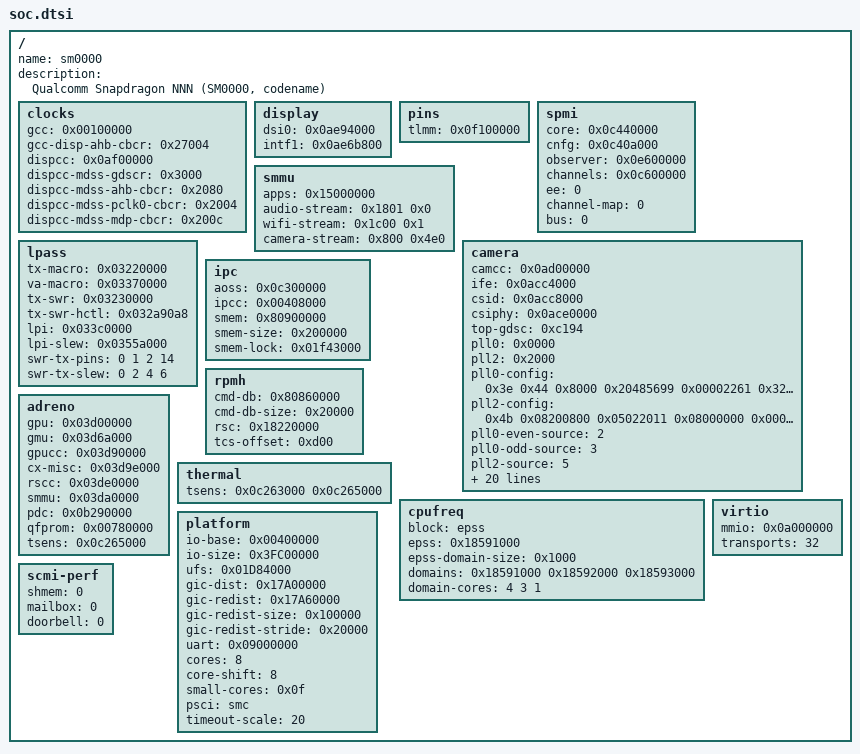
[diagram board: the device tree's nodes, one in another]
/dts-v1/;

// A SoC file with every key, explained: what goes in a package's soc.dtsi, beside its board.dts.
// `tools/boards.py new NAME --soc SOC --dts FILE` writes one with what your device tree says; this is the
// reference. A section is needed only by what uses it: a board with `features = <>;` and a "soft"
// backlight needs none of them. Addresses are the SoC's physical ones, as the Android device tree has
// them (the SoC's .dtsi).

/ {
	name = "sm0000";                        // what the board file gives as `soc`
	description = "Qualcomm Snapdragon NNN (SM0000, codename)";

	// The clocks the display block's registers need before they can be read: for a "dcs" backlight and
	// the feature "display-scan". The addresses are in the tree; the offsets are not -- they are in Linux's
	// clock drivers for the SoC (gcc-CODENAME.c, dispcc-CODENAME.c).
	clocks {
		gcc = <0x00100000>;             // clock-controller@100000 (qcom,CODENAME-gcc); the only key of this section
		                                // that the part drivers need
		gcc-disp-ahb-cbcr = <0x27004>;  // gcc_disp_ahb_clk: its .halt_reg
		dispcc = <0x0af00000>;          // clock-controller@af00000 (qcom,CODENAME-dispcc)
		dispcc-mdss-gdscr = <0x3000>;   // the display block's power switch (mdss_core_gdsc): its .gdscr
		dispcc-mdss-ahb-cbcr = <0x2080>; // disp_cc_mdss_ahb_clk
		dispcc-mdss-pclk0-cbcr = <0x2004>; // disp_cc_mdss_pclk0_clk  } optional: only looked at, by display_probe=1
		dispcc-mdss-mdp-cbcr = <0x200c>; // disp_cc_mdss_mdp_clk    }
	};

	display {
		dsi0 = <0x0ae94000>;            // the first DSI controller (cell-index 0), reg "dsi_ctrl"
		intf1 = <0x0ae6b800>;           // optional, for "display-scan": the same node's reg "mdp_intf_base"
	};

	// The SoC's own pins (TLMM), for the part drivers that drive them: the touch controllers', the speaker
	// amplifier's, the haptic motor's, the cameras'.
	pins {
		tlmm = <0x0f100000>;            // where GPIO 0's registers are; GPIO n's are 0x1000 n further. The pin
		                                // controller's node (qcom,CODENAME-pinctrl): in Linux's trees its reg; in
		                                // the vendor's, whose reg is the whole 16 MiB block, 0x100000 above it
	};

	// The PMIC arbiter (qcom,spmi-pmic-arb), by its reg-names: for the features "buttons-pmic",
	// "torch-pm8350c" and "camera-sm7325".
	spmi {
		core = <0x0c440000>;            // "core"
		cnfg = <0x0c40a000>;            // "cnfg"
		observer = <0x0e600000>;        // "obsrvr": reads
		channels = <0x0c600000>;        // "chnls": writes; optional, needed only by the drivers that write to a PMIC
		ee = <0>;                       // qcom,ee; optional, 0 if left out
		channel-map = <0>;              // arbiter version 8 only: its table of channels (the "core" node's
		//                              // second block); cnfg is then the table of owners, observer and
		//                              // channels 0x20 and 0x200 a channel (Linux spmi-pmic-arb.c).
		//                              // Optional; 0 or left out for versions 5 and 7
		bus = <0>;                      // arbiter version 7 only (two buses behind one arbiter): which of them,
		//                              // qcom,bus-id of the node, or the place of the bus's node under the
		//                              // arbiter's; cnfg above is then that bus's own. The
		//                              // drivers tell version 7 by the arbiter's version register.
		//                              // Optional; 0 (the first bus) if left out
	};

	// The SMMU between the SoC's devices and memory, for the part drivers that give a device its addresses
	// (the speakers' audio path, the cameras, Wi-Fi). The GPU's own is in adreno { }.
	smmu {
		apps = <0x15000000>;            // apps_smmu (the vendor's apps-smmu@15000000; Linux's iommu@15000000)
		audio-stream = <0x1801 0x0>;    // for "speaker-aw88261": the stream the audio DSP reads our samples on,
		                                // ID and mask: the iommus of qcom,msm-audio-ion
		wifi-stream = <0x1c00 0x1>;     // for "wifi-wcn6750": the Wi-Fi DSP's (the iommus of qcom,wpss or its
		                                // remoteproc node)
		camera-stream = <0x800 0x4e0>;  // for "camera-sm7325": the IFEs' (the iommus of msm_cam_smmu_ife)
	};

	// The camera subsystem's blocks, for the feature "camera-sm7325". From the SoC's -camera.dtsi (the
	// vendor's; tools/boards.py new does not read these yet).
	camera {
		camcc = <0x0ad00000>;           // the camera clock controller (qcom,CODENAME-camcc)
		ife = <0x0acc4000>;             // the image front end the driver takes frames through: here the first
		                                // "lite" one (qcom,ife-lite, reg "ife-lite")
		csid = <0x0acc8000>;            // ... and its CSI decoder (qcom,csid-lite, reg "csid-lite")
		csiphy = <0x0ace0000>;          // the first CSI receiver (qcom,csiphy, cell-index 0); the others follow at 0x2000
		// Where the clocks the driver switches are: offsets in camcc, as Linux's camcc-CODENAME.c has them (each
		// clock's .halt_reg for a branch, .cmd_rcgr for an RCG, .gdscr for the power domain, .offset for a PLL),
		// and the GCC's camera clocks in the GCC (gcc-CODENAME.c). How the PLLs are set up, and the dividers, are
		// the driver's: it speaks a Lucid PLL0 and a Zonda PLL2.
		top-gdsc = <0xc194>;            // titan_top_gdsc: the camera's top power domain
		pll0 = <0x0000>;                // cam_cc_pll0: the camera's clocks come from it
		pll2 = <0x2000>;                // cam_cc_pll2: an MCLK that is not the crystal's 19.2 MHz comes from it
		// How the two PLLs are configured, as cam_cc_pll0_config and cam_cc_pll2_config have it: PLL0's l, cal_l (if
		// the file has none, clk-alpha-pll.c's default for the PLL type: 0x44), alpha, config_ctl_val,
		// config_ctl_hi_val, config_ctl_hi1_val, user_ctl_val, user_ctl_hi_val, user_ctl_hi1_val; PLL2's l,
		// config_ctl_val, config_ctl_hi_val, config_ctl_hi1_val, user_ctl_val. The driver works out the rates
		// from them (19.2 MHz times L and alpha / 65536; PLL0's even and odd outputs divided as user_ctl_val says)
		// and divides its clocks to the rates it wants.
		pll0-config = <0x3e 0x44 0x8000 0x20485699 0x00002261 0x329a299c 0x00003101 0x00000805 0x00000000>;
		pll2-config = <0x4b 0x08200800 0x05022011 0x08000000 0x00000301>;
		pll0-even-source = <2>;         // which source of an RCG PLL0's even output is (its place in the parent map)
		pll0-odd-source = <3>;          // ... its odd output
		pll2-source = <5>;              // ... PLL2's early output, for an MCLK (in the MCLKs' parent map)
		mclk-rcg = <0xe000 0xe01c 0xe038 0xe054>;       // cam_cc_mclkN_clk_src, one for each MCLK (a sensor's mclk)
		mclk-branch = <0xe018 0xe034 0xe050 0xe06c>;    // cam_cc_mclkN_clk, in the same order
		csiphy-branch = <0xe0c8 0xe0ec 0xe110 0xe138>;  // cam_cc_csiphyN_clk, one for each CSI receiver (a sensor's csiphy)
		csiphy-timer-rcg = <0xe0ac 0xe0d0 0xe0f4 0xe11c>;       // cam_cc_csiNphytimer_clk_src, in the same order
		csiphy-timer-branch = <0xe0c4 0xe0e8 0xe10c 0xe134>;    // cam_cc_csiNphytimer_clk, in the same order
		slow-ahb-rcg = <0x7058>;        // cam_cc_slow_ahb_clk_src
		camnoc-axi-rcg = <0xc124>;      // cam_cc_camnoc_axi_clk_src
		cphy-rx-rcg = <0xa064>;         // cam_cc_cphy_rx_clk_src
		ife-csid-rcg = <0xc020>;        // cam_cc_ife_lite_0_csid_clk_src: of the IFE above
		ife-rcg = <0xc004>;             // cam_cc_ife_lite_0_clk_src
		cpas-ahb-branch = <0xc11c>;     // cam_cc_cpas_ahb_clk
		camnoc-axi-branch = <0xc140>;   // cam_cc_camnoc_axi_clk
		ife-csid-branch = <0xc038>;     // cam_cc_ife_lite_0_csid_clk
		ife-cphy-rx-branch = <0xc040>;  // cam_cc_ife_lite_0_cphy_rx_clk
		ife-branch = <0xc01c>;          // cam_cc_ife_lite_0_clk
		gcc-ahb-branch = <0x26004>;     // gcc_camera_ahb_clk, in the GCC
		gcc-xo-branch = <0x26028>;      // gcc_camera_xo_clk
		gcc-hf-axi-branch = <0x26010>;  // gcc_camera_hf_axi_clk
		gcc-sf-axi-branch = <0x2601c>;  // gcc_camera_sf_axi_clk
	};

	// The low-power audio subsystem's blocks on the microphones' path, for the feature "mic-wcd938x". From the
	// SoC's -audio.dtsi (the vendor's). tools/boards.py new finds the addresses and leaves the section commented
	// out, with the SoundWire pins to fill in.
	lpass {
		tx-macro = <0x03220000>;        // tx-macro@3220000 (qcom,tx-macro): the codec macro of the capture side
		va-macro = <0x03370000>;        // va-macro@3370000 (qcom,va-macro)
		tx-swr = <0x03230000>;          // the SoundWire master under the TX macro (qcom,swr-mstr): its reg
		tx-swr-hctl = <0x032a90a8>;     // ... and its hardware control register, its qcom,swrm-hctl-reg
		lpi = <0x033c0000>;             // the subsystem's own pins: lpi_pinctrl@33c0000 (qcom,lpi-pinctrl)
		lpi-slew = <0x0355a000>;        // ... and that node's qcom,slew-reg
		swr-tx-pins = <0 1 2 14>;       // the TX SoundWire master's pins among them, its clock first, then its data
		                                // lines (the lpi_pinctrl groups the swr-mstr node's pinctrl names)
		swr-tx-slew = <0 2 4 6>;        // each pin's field in that slew register (the vendor's pinctrl-lpi.c)
	};

	// The way to the SoC's other processors, for the features "adsp" and "wifi-wcn6750".
	ipc {
		aoss = <0x0c300000>;            // the always-on processor's mailbox: qcom,qmp-mbox (Linux: qcom,aoss-qmp), its reg
		ipcc = <0x00408000>;            // qcom,ipcc, its reg: what the processors ring each other through
		smem = <0x80900000>;            // the memory they share: the memory-region of the qcom,smem node
		smem-size = <0x200000>;         // ... and its size
		smem-lock = <0x01f43000>;       // the lock on it: hwlocks = <&tcsr_mutex N> of the qcom,smem node, which is
		                                // N x 0x1000 into the qcom,tcsr-mutex block (0x1f40000 + 3 x 0x1000)
	};

	// RPMh: for the features "ddr-rpmh", "adsp" and "gpu-a660", and for the part drivers that ask it for a
	// supply (the touch controllers', the speaker amplifier's, the cameras', Wi-Fi's).
	rpmh {
		cmd-db = <0x80860000>;          // the reserved-memory node with compatible "qcom,cmd-db": its address
		cmd-db-size = <0x20000>;        // ... and size
		rsc = <0x18220000>;             // the qcom,rpmh-rsc with qcom,drv-id = <2> (apps_rsc): its reg "drv-2"
		tcs-offset = <0xd00>;           // qcom,tcs-offset of that node
	};

	// The Adreno's blocks, for the feature "gpu-a660". From the SoC's -gpu.dtsi (qcom,kgsl-3d0 and qcom,gmu,
	// by their reg-names) and its main .dtsi. What differs between phones is the board's gpu { }.
	adreno {
		gpu = <0x03d00000>;             // qcom,kgsl-3d0, reg "kgsl_3d0_reg_memory": the 3D core
		gmu = <0x03d6a000>;             // qcom,gmu, reg "kgsl_gmu_reg"
		gpucc = <0x03d90000>;           // the GPU's clock controller (qcom,CODENAME-gpucc)
		cx-misc = <0x03d9e000>;         // qcom,kgsl-3d0, reg "cx-misc"
		rscc = <0x03de0000>;            // qcom,kgsl-3d0, reg "rscc"
		smmu = <0x03da0000>;            // the GPU's SMMU (kgsl-smmu)
		pdc = <0x0b290000>;             // qcom,gmu, reg "kgsl_gmu_pdc_cfg"
		qfprom = <0x00780000>;          // the fuses (qfprom), where the board's gpu { } speed-fuse and gaming-fuse are
		tsens = <0x0c265000>;           // optional: the TSENS controller with the GPU's sensors, read once a minute
	};

	// Temperature, for a board's thermal { }.
	thermal {
		tsens = <0x0c263000 0x0c265000>; // the TSENS controllers (at most eight), reg "tsens_tm_physical"
	};

	// The cores' frequency hardware, for the feature "cpufreq-epss" and a board's thermal { }: EPSS on the SM8350,
	// SM7325, SC7280 and every chip after them, the OSM's firmware before it (SDM845, SM8150, SM8250, SC7180,
	// SM6350, SM7225). The node is qcom,cpufreq-epss or qcom,cpufreq-hw (the vendor's qcom,cpufreq-hw-epss or
	// qcom,cpufreq-hw); tools/boards.py new --dts reads it, the layout with it.
	cpufreq {
		block = "epss";                 // optional: "epss" (the default) or "osm", the registers' layout
		                                // (drivers/board/cpufreq_hw.h): "osm" for a qcom,cpufreq-hw node
		epss = <0x18591000>;            // the first of its "freq-domainN" regs
		epss-domain-size = <0x1000>;    // their size (at least 0x324 for EPSS, 0x924 for the OSM), and the distance
		                                // from one to the next unless domains says otherwise
		domains = <0x18591000 0x18592000 0x18593000>; // optional: each "freq-domainN", where they are not one
		                                // size apart (an SM8150's are not); the first is epss
		domain-cores = <4 3 1>;         // how many cores each group has, in the cores' order (the cpu@ nodes'
		                                // qcom,freq-domain); one to four groups, together platform { } cores
	};

	// What the loader (arch/arm64/boot/) tells the kernel of the machine, for boards with a loader { } section.
	platform {
		io-base = <0x00400000>;         // one window over the SoC's peripherals; never 0. Not in a device tree;
		                                // needed once a board has a loader { } section
		io-size = <0x3FC00000>;         // (these two are what the Snapdragon 7-series ports use)
		ufs = <0x01D84000>;             // optional: the UFS host controller (the ufshc node's reg "ufs_mem"), for the
		                                // loader's and the kernel's own requests to the storage (ufs_native=)
		gic-dist = <0x17A00000>;        // the arm,gic-v3 node's reg: its first entry
		gic-redist = <0x17A60000>;      // ... its second
		gic-redist-size = <0x100000>;   // optional: the redistributors' region; 1 MB (eight cores) if left out
		gic-redist-stride = <0x20000>;  // optional: the distance between redistributors; as the GIC says if left out
		uart = <0x09000000>;            // optional: a PL011 for the kernel's serial console (the emulator has one)
		cores = <8>;                    // the cpu@ nodes
		core-shift = <8>;               // where the core's number is in its reg: 8 for 0x000, 0x100 ..., 0 for 0, 1 ...
		small-cores = <0x0f>;           // optional: a bit for each core of the lowest capacity-dmips-mhz
		psci = "smc";                   // the psci node's method: "smc" or "hvc"
		timeout-scale = <20>;           // optional: how many times longer the kernel waits for a lock; for emulators
	};

	virtio {
		mmio = <0x0a000000>;            // for "virtio" (an emulator): the first virtio,mmio node's reg
		transports = <32>;              // how many of those nodes follow it, 0x200 bytes apart
	};

	// Optional SCMI performance channel for the cpufreq-scmi feature: a chip whose cores' speeds are the firmware's
	// (SM8845).
	scmi-perf {
		shmem = <0>;                    // shared-memory channel's physical address
		mailbox = <0>;                  // mailbox's physical base
		doorbell = <0>;                 // aligned register offset inside the mailbox page
	};
};
